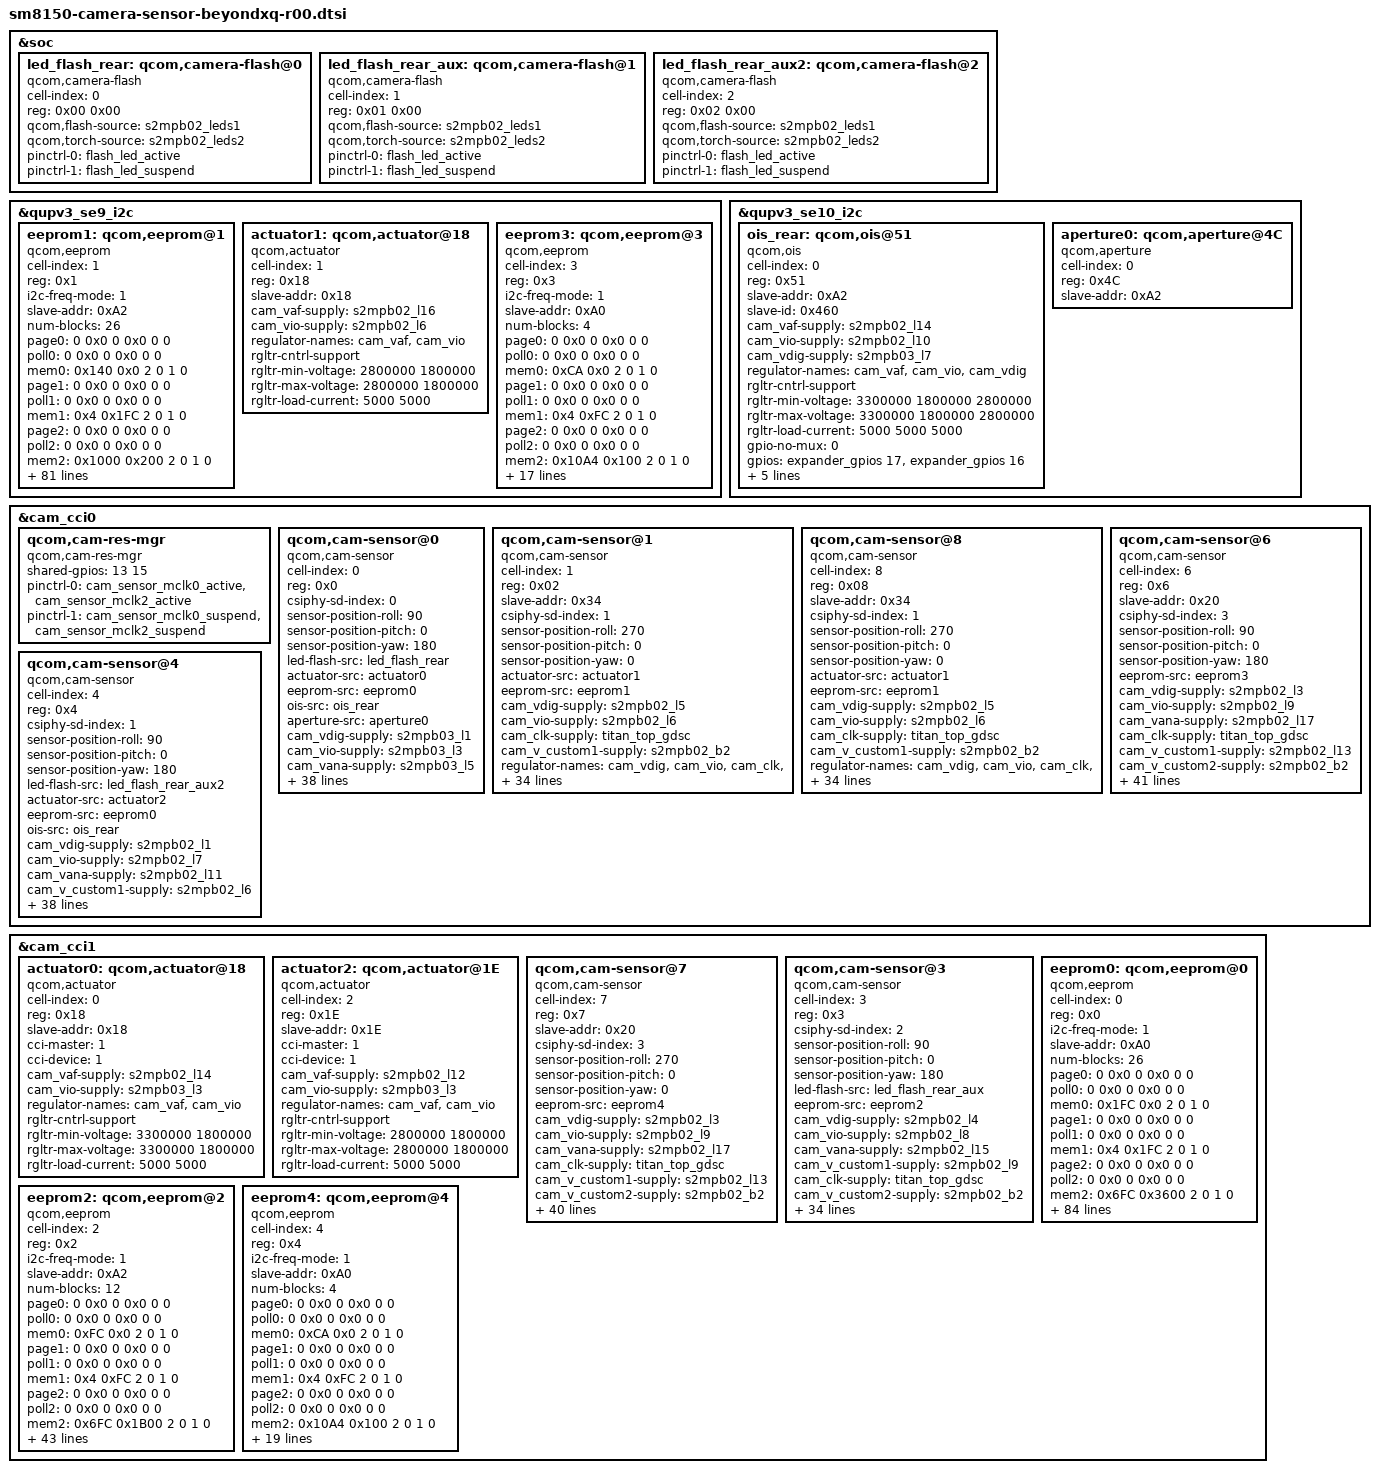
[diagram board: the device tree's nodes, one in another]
/*
 * Copyright (c) 2018, The Linux Foundation. All rights reserved.
 *
 * This program is free software; you can redistribute it and/or modify
 * it under the terms of the GNU General Public License version 2 and
 * only version 2 as published by the Free Software Foundation.
 *
 * This program is distributed in the hope that it will be useful,
 * but WITHOUT ANY WARRANTY; without even the implied warranty of
 * MERCHANTABILITY or FITNESS FOR A PARTICULAR PURPOSE.  See the
 * GNU General Public License for more details.
 */

&soc{
	led_flash_rear: qcom,camera-flash@0 {
		cell-index = <0>;
		reg = <0x00 0x00>;
		compatible = "qcom,camera-flash";
		qcom,flash-source = <&s2mpb02_leds1>;
		qcom,torch-source = <&s2mpb02_leds2>;
		pinctrl-names = "cam_default", "cam_suspend";
		pinctrl-0 = <&flash_led_active>;
		pinctrl-1 = <&flash_led_suspend>;
		status = "ok";
	};

	led_flash_rear_aux: qcom,camera-flash@1 {
		cell-index = <1>;
		reg = <0x01 0x00>;
		compatible = "qcom,camera-flash";
		qcom,flash-source = <&s2mpb02_leds1>;
		qcom,torch-source = <&s2mpb02_leds2>;
		pinctrl-names = "cam_default", "cam_suspend";
		pinctrl-0 = <&flash_led_active>;
		pinctrl-1 = <&flash_led_suspend>;
		status = "ok";
	};

	led_flash_rear_aux2: qcom,camera-flash@2 {
		cell-index = <2>;
		reg = <0x02 0x00>;
		compatible = "qcom,camera-flash";
		qcom,flash-source = <&s2mpb02_leds1>;
		qcom,torch-source = <&s2mpb02_leds2>;
		pinctrl-names = "cam_default", "cam_suspend";
		pinctrl-0 = <&flash_led_active>;
		pinctrl-1 = <&flash_led_suspend>;
		status = "ok";
	};
};

&qupv3_se9_i2c {
	status = "ok";

	eeprom1: qcom,eeprom@1 {
		cell-index = <1>;
		reg = <0x1>;
		compatible = "qcom,eeprom";
		i2c-freq-mode = <1>;
		slave-addr = <0xA2>;
		//eeprom-name= "n24c256";

		num-blocks = <26>;
		page0 = <0 0x0 0 0x0 0 0>;
		poll0 = <0 0x0 0 0x0 0 0>;
		mem0 = <0x140 0x0 2 0 1 0>;
		page1 = <0 0x0 0 0x0 0 0>;
		poll1 = <0 0x0 0 0x0 0 0>;
		mem1 = <0x4 0x1FC 2 0 1 0>;
		page2 = <0 0x0 0 0x0 0 0>;
		poll2 = <0 0x0 0 0x0 0 0>;
		mem2 = <0x1000 0x200 2 0 1 0>;
		page3 = <0 0x0 0 0x0 0 0>;
		poll3 = <0 0x0 0 0x0 0 0>;
		mem3 = <0x4 0x1200 2 0 1 0>;
		page4 = <0 0x0 0 0x0 0 0>;
		poll4 = <0 0x0 0 0x0 0 0>;
		mem4 = <0x420 0x1204 2 0 1 0>;
		page5 = <0 0x0 0 0x0 0 0>;
		poll5 = <0 0x0 0 0x0 0 0>;
		mem5 = <0x4 0x1624 2 0 1 0>;
		page6 = <0 0x0 0 0x0 0 0>;
		poll6 = <0 0x0 0 0x0 0 0>;
		mem6 = <0x2C 0x1630 2 0 1 0>;
		page7 = <0 0x0 0 0x0 0 0>;
		poll7 = <0 0x0 0 0x0 0 0>;
		mem7 = <0x4 0x165C 2 0 1 0>;
		page8 = <0 0x0 0 0x0 0 0>;
		poll8 = <0 0x0 0 0x0 0 0>;
		mem8 = <0x2C 0x1660 2 0 1 0>;
		page9 = <0 0x0 0 0x0 0 0>;
		poll9 = <0 0x0 0 0x0 0 0>;
		mem9 = <0x4 0x168C 2 0 1 0>;
		page10 = <0 0x0 0 0x0 0 0>;
		poll10 = <0 0x0 0 0x0 0 0>;
		mem10 = <0x6FC 0x1690 2 0 1 0>;
		page11 = <0 0x0 0 0x0 0 0>;
		poll11 = <0 0x0 0 0x0 0 0>;
		mem11 = <0x4 0x1D8C 2 0 1 0>;
		page12 = <0 0x0 0 0x0 0 0>;
		poll12 = <0 0x0 0 0x0 0 0>;
		mem12 = <0x1BE0 0x200 2 0 1 0>;
		page13 = <0 0x0 0 0x0 0 0>;
		poll13 = <0 0x0 0 0x0 0 0>;
		mem13 = <0x4 0x1DFC 2 0 1 0>;
		page14 = <0 0x0 0 0x0 0 0>;
		poll14 = <0 0x0 0 0x0 0 0>;
		mem14 = <0x2C 0x1E00 2 0 1 0>;
		page15 = <0 0x0 0 0x0 0 0>;
		poll15 = <0 0x0 0 0x0 0 0>;
		mem15 = <0x4 0x1E2C 2 0 1 0>;
		page16 = <0 0x0 0 0x0 0 0>;
		poll16 = <0 0x0 0 0x0 0 0>;
		mem16 = <0x2C 0x1E30 2 0 1 0>;
		page17 = <0 0x0 0 0x0 0 0>;
		poll17 = <0 0x0 0 0x0 0 0>;
		mem17 = <0x4 0x1E5C 2 0 1 0>;
		page18 = <0 0x0 0 0x0 0 0>;
		poll18 = <0 0x0 0 0x0 0 0>;
		mem18 = <0x6FC 0x1E60 2 0 1 0>;
		page19 = <0 0x0 0 0x0 0 0>;
		poll19 = <0 0x0 0 0x0 0 0>;
		mem19 = <0x4 0x255C 2 0 1 0>;
		page20 = <0 0x0 0 0x0 0 0>;
		poll20 = <0 0x0 0 0x0 0 0>;
		mem20 = <0x6C 0x2560 2 0 1 0>;
		page21 = <0 0x0 0 0x0 0 0>;
		poll21 = <0 0x0 0 0x0 0 0>;
		mem21 = <0x4 0x25CC 2 0 1 0>;
		page22 = <0 0x0 0 0x0 0 0>;
		poll22 = <0 0x0 0 0x0 0 0>;
		mem22 = <0x80C 0x25D0 2 0 1 0>;
		page23 = <0 0x0 0 0x0 0 0>;
		poll23 = <0 0x0 0 0x0 0 0>;
		mem23 = <0x4 0x2DDC 2 0 1 0>;
		page24 = <0 0x0 0 0x0 0 0>;
		poll24 = <0 0x0 0 0x0 0 0>;
		mem24 = <0xFE0 0x1E00 2 0 1 0>;
		page25 = <0 0x0 0 0x0 0 0>;
		poll25 = <0 0x0 0 0x0 0 0>;
		mem25 = <0x4 0x2DFC 2 0 1 0>;
		//total-size = <0x2E00>;

		qcom,cam-power-seq-type = "cam_vio";
		qcom,cam-power-seq-cfg-val = <1>;
		qcom,cam-power-seq-delay = <0>;

		cam_vio-supply = <&s2mpb02_l6>; /* VDD_VTCAM_IO_1P8 */
		regulator-names = "cam_vio";
		rgltr-cntrl-support;
		rgltr-min-voltage = <1800000>;
		rgltr-max-voltage = <1800000>;
		rgltr-load-current = <5000>;
		gpio-no-mux = <1>;
		sensor-position = <1>;
		sensor-mode = <0>;
		status = "ok";
	};

	actuator1: qcom,actuator@18 {
		cell-index = <1>;
		reg = <0x18>;
		slave-addr = <0x18>;
		compatible = "qcom,actuator";
		cam_vaf-supply = <&s2mpb02_l16>;
		cam_vio-supply = <&s2mpb02_l6>;
		regulator-names = "cam_vaf", "cam_vio";
		rgltr-cntrl-support;
		rgltr-min-voltage = <2800000 1800000>;
		rgltr-max-voltage = <2800000 1800000>;
		rgltr-load-current = <5000 5000>;
		status = "ok";
	};

	eeprom3: qcom,eeprom@3 {
		cell-index = <3>; /*REAR TOF EEPROM*/
		reg = <0x3>;
		compatible = "qcom,eeprom";
		i2c-freq-mode = <1>;
		slave-addr = <0xA0>;
		//eeprom-name= "n24c256";

		num-blocks = <4>;
		page0 = <0 0x0 0 0x0 0 0>;
		poll0 = <0 0x0 0 0x0 0 0>;
		mem0 = <0xCA 0x0 2 0 1 0>;
		page1 = <0 0x0 0 0x0 0 0>;
		poll1 = <0 0x0 0 0x0 0 0>;
		mem1 = <0x4 0xFC 2 0 1 0>;
		page2 = <0 0x0 0 0x0 0 0>;
		poll2 = <0 0x0 0 0x0 0 0>;
		mem2 = <0x10A4 0x100 2 0 1 0>;
		page3 = <0 0x0 0 0x0 0 0>;
		poll3 = <0 0x0 0 0x0 0 0>;
		mem3 = <0x4 0x18FC 2 0 1 0>;
		//total-size = <0x1900>;

		qcom,cam-power-seq-type = "cam_vio", "cam_v_custom1";
		qcom,cam-power-seq-cfg-val = <1 1>;
		qcom,cam-power-seq-delay = <0 0>;

		cam_vio-supply = <&s2mpb02_l6>; /* VDD_VTCAM_IO_1P8 */
		cam_v_custom1-supply = <&s2mpb02_l9>; /* VDD_TOF_IO_1P8 */
		regulator-names = "cam_vio", "cam_v_custom1";
		rgltr-cntrl-support;
		rgltr-min-voltage = <1800000 1800000>;
		rgltr-max-voltage = <1800000 1800000>;
		rgltr-load-current = <5000 5000>;
		gpio-no-mux = <1>;
		sensor-position = <0>;
		sensor-mode = <0>;
		status = "ok";
	};
};

&qupv3_se10_i2c {
	status = "ok";
	ois_rear: qcom,ois@51  {
		compatible = "qcom,ois";
		cell-index = <0>;
		reg = <0x51>;
		slave-addr = <0xA2>;
		slave-id = <0x460>;
		cam_vaf-supply = <&s2mpb02_l14>; /* VDD_MAINCAM_AF_3P3 */
		cam_vio-supply = <&s2mpb02_l10>; /* VDD_OIS_MCU_1P8 */
		cam_vdig-supply = <&s2mpb03_l7>; /* VDD_CAM_OIS_2P8 */
		regulator-names = "cam_vaf", "cam_vio", "cam_vdig";
		rgltr-cntrl-support;
		rgltr-min-voltage = <3300000 1800000 2800000>;
		rgltr-max-voltage = <3300000 1800000 2800000>;
		rgltr-load-current = <5000 5000 5000>;
		gpio-no-mux = <0>;
		gpios = <&expander_gpios 17 0>, // RESET
			<&expander_gpios 16 0>; // BOOT0
		gpio-reset = <0>;
		gpio-custom1 = <1>;
		gpio-req-tbl-num = <0 1>;
		gpio-req-tbl-flags = <0 0>;
		gpio-req-tbl-label = "MCU_RESET0", "MCU_BOOT0";
		status = "ok";
	};

	aperture0: qcom,aperture@4C {
		cell-index = <0>;
		reg = <0x4C>;
		compatible = "qcom,aperture";
		slave-addr = <0xA2>;
		status = "ok";
	};
};

&cam_cci0 {
	qcom,cam-res-mgr {
		compatible = "qcom,cam-res-mgr";
		shared-gpios = <13 15>;
		pinctrl-names = "cam_res_mgr_default", "cam_res_mgr_suspend";
		status = "ok";
		pinctrl-0 = <&cam_sensor_mclk0_active
		    &cam_sensor_mclk2_active>;
		pinctrl-1 = <&cam_sensor_mclk0_suspend
    		&cam_sensor_mclk2_suspend>;
	};

	qcom,cam-sensor@0 {
		cell-index = <0>; /*REAR MAIN*/
		compatible = "qcom,cam-sensor";
		reg = <0x0>;
		csiphy-sd-index = <0>;
		sensor-position-roll = <90>;
		sensor-position-pitch = <0>;
		sensor-position-yaw = <180>;
		led-flash-src = <&led_flash_rear>;
		actuator-src = <&actuator0>;
		eeprom-src = <&eeprom0>;
		ois-src = <&ois_rear>;
		aperture-src = <&aperture0>;
		cam_vdig-supply = <&s2mpb03_l1>;
		cam_vio-supply = <&s2mpb03_l3>;
		cam_vana-supply = <&s2mpb03_l5>;
		cam_v_custom1-supply = <&s2mpb03_l6>;
		cam_v_custom2-supply = <&s2mpb03_l2>;
		cam_v_custom3-supply = <&s2mpb03_l4>;
		cam_v_custom4-supply = <&s2mpb02_l9>; /* VDD_TOF_IO_1P8 */
		cam_clk-supply = <&titan_top_gdsc>;
		regulator-names = "cam_vdig", "cam_vio", "cam_vana", "cam_v_custom1", "cam_v_custom2", "cam_v_custom3", "cam_v_custom4", "cam_clk";
		rgltr-cntrl-support;
		rgltr-min-voltage = <1025000 1800000 2400000 2800000 1100000 1025000 1800000 0>;
		rgltr-max-voltage = <1025000 1800000 2400000 2800000 1100000 1025000 1800000 0>;
		rgltr-load-current = <200000 200000 5000 200000 5000 5000 5000 0>;
		gpio-no-mux = <0>;
		use-shared-clk;
		gpios = <&tlmm 13 0>, /* MCLK */
			<&expander_gpios 12 0>; /* RESET */
		gpio-reset = <1>;
		gpio-req-tbl-num = <0 1>;
		gpio-req-tbl-flags = <1 0>;
		gpio-req-tbl-label = "CAMIF_MCLK0",
					"CAM_RESET0";
		sensor-mode = <0>;
		cci-master = <0>;
		status = "ok";
		clocks = <&clock_camcc CAM_CC_MCLK0_CLK>;
		clock-names = "cam_clk";
		clock-cntl-level = "turbo";
		clock-rates = <19200000>;

		cam,isp = <0>;                  // 0 : INT , 1 : EXT , 2 : SOC
		cam,cal_memory = <2>;           // 0 : N , 1 : FROM , 2 : EEPROM , 3 : OTP
		cam,read_version = <1>;         // 0 : SYSFS , 1 : CAMON
		cam,core_voltage = <1>;         // 0 : N , 1 : Y
		cam,upgrade = <2>;              // 0 : N , 1 : SYSFS , 2 : CAMON
		cam,fw_write = <3>;             // 0 : N , 1 : OS , 2 : SD , 3 : ALL
		cam,fw_dump = <1>;              // 0 : N , 1 : Y
		cam,companion_chip = <0>;       // 0 : N , 1 : Y
		cam,ois = <1>;                  // 0 : N , 1 : Y
		cam,dual_open = <0>;            // 0 : N , 1 : Y
		cam,valid = <1>;                // 0 : N , 1 : Y
	};

 	qcom,cam-sensor@1 {
		cell-index = <1>; //VT 10M
		compatible = "qcom,cam-sensor";
		reg = <0x02>;
		slave-addr = <0x34>;
		csiphy-sd-index = <1>;
		sensor-position-roll = <270>;
		sensor-position-pitch = <0>;
		sensor-position-yaw = <0>;
		actuator-src = <&actuator1>;
		eeprom-src = <&eeprom1>;
		cam_vdig-supply = <&s2mpb02_l5>;
		cam_vio-supply = <&s2mpb02_l6>;
		cam_clk-supply = <&titan_top_gdsc>;
		cam_v_custom1-supply = <&s2mpb02_b2>;
		regulator-names = "cam_vdig", "cam_vio", "cam_clk", "cam_v_custom1";
		rgltr-cntrl-support;
		rgltr-min-voltage = <1050000 1800000 0 1300000>;
		rgltr-max-voltage = <1050000 1800000 0 1300000>;
		rgltr-load-current = <200000 200000 0 200000>;
		gpio-no-mux = <0>;
		use-shared-clk;
		pinctrl-names = "cam_default", "cam_suspend";
		pinctrl-0 = <&cam_sensor_active_front
			&cam_sensor_mipi_sw_active>;
		pinctrl-1 = <&cam_sensor_suspend_front
			&cam_sensor_mipi_sw_suspend>;
		gpios = <&tlmm 15 0>,
			<&tlmm 82 0>,
			<&tlmm 116 0>;  //SUBCAM_SEL
		gpio-reset = <1>;
		gpio-custom1 = <2>;
		gpio-req-tbl-num = <0 1 2>;
		gpio-req-tbl-flags = <1 0 0>;
		gpio-req-tbl-label = "CAMIF_MCLK2",
					"CAM_RESET2",
					"SUBCAM_SEL";
                sensor-mode = <0>;
		cci-master = <1>;
		status = "ok";
		clocks = <&clock_camcc CAM_CC_MCLK2_CLK>;
		clock-names = "cam_clk";
		clock-cntl-level = "turbo";
		clock-rates = <24000000>;

		cam,isp = <0>;                  // 0 : INT , 1 : EXT , 2 : SOC
		cam,cal_memory = <2>;           // 0 : N , 1 : FROM , 2 : EEPROM , 3 : OTP
		cam,read_version = <0>;         // 0 : SYSFS , 1 : CAMON
		cam,core_voltage = <0>;         // 0 : N , 1 : Y
		cam,upgrade = <0>;              // 0 : N , 1 : SYSFS , 2 : CAMON
		cam,fw_write = <0>;             // 0 : N , 1 : OS , 2 : SD , 3 : ALL
		cam,fw_dump = <0>;              // 0 : N , 1 : Y
		cam,companion_chip = <0>;       // 0 : N , 1 : Y
		cam,ois = <0>;                  // 0 : N , 1 : Y
		cam,dual_open = <0>;            // 0 : N , 1 : Y
		cam,valid = <1>;                // 0 : N , 1 : Y
	};

 	qcom,cam-sensor@8 {
		cell-index = <8>; //VT 10M FULL
		compatible = "qcom,cam-sensor";
		reg = <0x08>;
		slave-addr = <0x34>;
		csiphy-sd-index = <1>;
		sensor-position-roll = <270>;
		sensor-position-pitch = <0>;
		sensor-position-yaw = <0>;
		actuator-src = <&actuator1>;
		eeprom-src = <&eeprom1>;
		cam_vdig-supply = <&s2mpb02_l5>;
		cam_vio-supply = <&s2mpb02_l6>;
		cam_clk-supply = <&titan_top_gdsc>;
		cam_v_custom1-supply = <&s2mpb02_b2>;
		regulator-names = "cam_vdig", "cam_vio", "cam_clk", "cam_v_custom1";
		rgltr-cntrl-support;
		rgltr-min-voltage = <1050000 1800000 0 1300000>;
		rgltr-max-voltage = <1050000 1800000 0 1300000>;
		rgltr-load-current = <200000 200000 0 200000>;
		gpio-no-mux = <0>;
		use-shared-clk;
		pinctrl-names = "cam_default", "cam_suspend";
		pinctrl-0 = <&cam_sensor_active_front
			&cam_sensor_mipi_sw_active>;
		pinctrl-1 = <&cam_sensor_suspend_front
			&cam_sensor_mipi_sw_suspend>;
		gpios = <&tlmm 15 0>,
			<&tlmm 82 0>,
			<&tlmm 116 0>;  //SUBCAM_SEL
		gpio-reset = <1>;
		gpio-custom1 = <2>;
		gpio-req-tbl-num = <0 1 2>;
		gpio-req-tbl-flags = <1 0 0>;
		gpio-req-tbl-label = "CAMIF_MCLK2",
					"CAM_RESET2",
					"SUBCAM_SEL";
                sensor-mode = <0>;
		cci-master = <1>;
		status = "ok";
		clocks = <&clock_camcc CAM_CC_MCLK2_CLK>;
		clock-names = "cam_clk";
		clock-cntl-level = "turbo";
		clock-rates = <24000000>;

		cam,isp = <0>;                  // 0 : INT , 1 : EXT , 2 : SOC
		cam,cal_memory = <2>;           // 0 : N , 1 : FROM , 2 : EEPROM , 3 : OTP
		cam,read_version = <0>;         // 0 : SYSFS , 1 : CAMON
		cam,core_voltage = <0>;         // 0 : N , 1 : Y
		cam,upgrade = <0>;              // 0 : N , 1 : SYSFS , 2 : CAMON
		cam,fw_write = <0>;             // 0 : N , 1 : OS , 2 : SD , 3 : ALL
		cam,fw_dump = <0>;              // 0 : N , 1 : Y
		cam,companion_chip = <0>;       // 0 : N , 1 : Y
		cam,ois = <0>;                  // 0 : N , 1 : Y
		cam,dual_open = <0>;            // 0 : N , 1 : Y
		cam,valid = <1>;                // 0 : N , 1 : Y
	};
	qcom,cam-sensor@6 {
		cell-index = <6>; // REAR TOF
		compatible = "qcom,cam-sensor";
		reg = <0x6>;
		slave-addr = <0x20>;
		csiphy-sd-index = <3>;
		sensor-position-roll = <90>;
		sensor-position-pitch = <0>;
		sensor-position-yaw = <180>;
		eeprom-src = <&eeprom3>;
		cam_vdig-supply = <&s2mpb02_l3>;
		cam_vio-supply = <&s2mpb02_l9>;
		cam_vana-supply = <&s2mpb02_l17>;
		cam_clk-supply = <&titan_top_gdsc>;
		cam_v_custom1-supply = <&s2mpb02_l13>;
		cam_v_custom2-supply = <&s2mpb02_b2>;
		cam_v_custom3-supply = <&s2mpb02_l6>;
		regulator-names = "cam_vdig", "cam_vio", "cam_vana", "cam_clk", "cam_v_custom1", "cam_v_custom2", "cam_v_custom3";
		rgltr-cntrl-support;
		rgltr-min-voltage = <1200000 1800000 2800000 0 3300000 1300000 1800000>;
		rgltr-max-voltage = <1200000 1800000 2800000 0 3300000 1300000 1800000>;
		rgltr-load-current = <200000 200000 5000 0 200000 200000 200000>;
		gpio-no-mux = <0>;
		pinctrl-names = "cam_default", "cam_suspend";
		pinctrl-0 = <&cam_sensor_mclk3_active
			&cam_sensor_mipi_sw1_active>;
		pinctrl-1 = <&cam_sensor_mclk3_suspend
			&cam_sensor_mipi_sw1_suspend>;
		gpios = <&tlmm 16 0>,  // MCLK
			<&expander_gpios 15 0>, // TOF RESET
			<&tlmm 7 0>,
			<&expander_gpios 20 0>; // TOF BB ENABLE;
		gpio-reset = <1>;
		gpio-custom1 = <2>;
		gpio-custom2 = <3>;
		gpio-req-tbl-num = <0 1 2 3>;
		gpio-req-tbl-flags = <1 0 0 0>;
		gpio-req-tbl-label = "CAMIF_MCLK3",
					"CAM_RESET3",
					"TOFCAM_SEL",
					"TOF_BB_ENABLE";
        sensor-mode = <0>;
		cci-master = <1>;
		status = "ok";
		clocks = <&clock_camcc CAM_CC_MCLK3_CLK>;
		clock-names = "cam_clk";
		clock-cntl-level = "turbo";
		clock-rates = <24000000>;

		cam,isp = <0>;                  // 0 : INT , 1 : EXT , 2 : SOC
		cam,cal_memory = <0>;           // 0 : N , 1 : FROM , 2 : EEPROM , 3 : OTP
		cam,read_version = <0>;         // 0 : SYSFS , 1 : CAMON
		cam,core_voltage = <0>;         // 0 : N , 1 : Y
		cam,upgrade = <0>;              // 0 : N , 1 : SYSFS , 2 : CAMON
		cam,fw_write = <0>;             // 0 : N , 1 : OS , 2 : SD , 3 : ALL
		cam,fw_dump = <0>;              // 0 : N , 1 : Y
		cam,companion_chip = <0>;       // 0 : N , 1 : Y
		cam,ois = <0>;                  // 0 : N , 1 : Y
		cam,dual_open = <0>;            // 0 : N , 1 : Y
		cam,valid = <1>;                // 0 : N , 1 : Y
	};

	qcom,cam-sensor@4 {
		cell-index = <4>; /* REAR TELE */
		compatible = "qcom,cam-sensor";
		reg = <0x4>;
		csiphy-sd-index = <1>;
		sensor-position-roll = <90>;
		sensor-position-pitch = <0>;
		sensor-position-yaw = <180>;
		led-flash-src = <&led_flash_rear_aux2>;
		actuator-src = <&actuator2>;
		eeprom-src = <&eeprom0>;
		ois-src = <&ois_rear>;
		cam_vdig-supply = <&s2mpb02_l1>;
		cam_vio-supply = <&s2mpb02_l7>;
		cam_vana-supply = <&s2mpb02_l11>;
		cam_v_custom1-supply = <&s2mpb02_l6>; /* VDD_VT10M_IO_1P8 */
		cam_clk-supply = <&titan_top_gdsc>;
		cam_v_custom2-supply = <&s2mpb02_b2>;
		regulator-names = "cam_vdig", "cam_vio", "cam_vana", "cam_v_custom1", "cam_clk", "cam_v_custom2";
		rgltr-cntrl-support;
		rgltr-min-voltage = <1025000 1800000 2800000 1800000 0 1300000>;
		rgltr-max-voltage = <1025000 1800000 2800000 1800000 0 1300000>;
		rgltr-load-current = <200000 200000 200000 5000 0 200000>;
		gpio-no-mux = <0>;
		use-shared-clk;
		pinctrl-names = "cam_default", "cam_suspend";
		pinctrl-0 = <&cam_sensor_mipi_sw_active>;
		pinctrl-1 = <&cam_sensor_mipi_sw_suspend>;
		gpios = <&tlmm 13 0>, /* MCLK */
			<&expander_gpios 14 0>, /* RESET */
			<&tlmm 116 0>; /* SUBCAM_SEL */
		gpio-reset = <1>;
		gpio-custom1 = <2>;
		gpio-req-tbl-num = <0 1 2>;
		gpio-req-tbl-flags = <1 0 1>;
		gpio-req-tbl-label = "CAMIF_MCLK0",
					"CAM_SUB_RESET",
					"SUBCAM_SEL";
		sensor-mode = <0>;
		cci-master = <1>;
		status = "ok";
		clocks = <&clock_camcc CAM_CC_MCLK0_CLK>;
		clock-names = "cam_clk";
		clock-cntl-level = "turbo";
		clock-rates = <19200000>;

		cam,isp = <0>;                  // 0 : INT , 1 : EXT , 2 : SOC
		cam,cal_memory = <2>;           // 0 : N , 1 : FROM , 2 : EEPROM , 3 : OTP
		cam,read_version = <0>;         // 0 : SYSFS , 1 : CAMON
		cam,core_voltage = <0>;         // 0 : N , 1 : Y
		cam,upgrade = <0>;              // 0 : N , 1 : SYSFS , 2 : CAMON
		cam,fw_write = <0>;             // 0 : N , 1 : OS , 2 : SD , 3 : ALL
		cam,fw_dump = <0>;              // 0 : N , 1 : Y
		cam,companion_chip = <0>;       // 0 : N , 1 : Y
		cam,ois = <1>;                  // 0 : N , 1 : Y
		cam,dual_open = <0>;            // 0 : N , 1 : Y
		cam,valid = <1>;                // 0 : N , 1 : Y
	};
};

&cam_cci1 {
	actuator0: qcom,actuator@18 { /* Wide */
		cell-index = <0>;
		reg = <0x18>;
		slave-addr = <0x18>;
		compatible = "qcom,actuator";
		cci-master = <1>;
		cci-device = <1>;
		cam_vaf-supply = <&s2mpb02_l14>;
		cam_vio-supply = <&s2mpb03_l3>;
		regulator-names = "cam_vaf", "cam_vio";
		rgltr-cntrl-support;
		rgltr-min-voltage = <3300000 1800000>;
		rgltr-max-voltage = <3300000 1800000>;
		rgltr-load-current = <5000 5000>;
		status = "ok";
	};

	actuator2: qcom,actuator@1E { /* Tele */
		cell-index = <2>;
		reg = <0x1E>;
		slave-addr = <0x1E>;
		compatible = "qcom,actuator";
		cci-master = <1>;
		cci-device = <1>;
		cam_vaf-supply = <&s2mpb02_l12>;
		cam_vio-supply = <&s2mpb03_l3>;
		regulator-names = "cam_vaf", "cam_vio";
		rgltr-cntrl-support;
		rgltr-min-voltage = <2800000 1800000>;
		rgltr-max-voltage = <2800000 1800000>;
		rgltr-load-current = <5000 5000>;
		status = "ok";
	};

	qcom,cam-sensor@7 {
		cell-index = <7>;   //FRONT TOF
		compatible = "qcom,cam-sensor";
		reg = <0x7>;
		slave-addr = <0x20>;
		csiphy-sd-index = <3>;
		sensor-position-roll = <270>;
		sensor-position-pitch = <0>;
		sensor-position-yaw = <0>;
		eeprom-src = <&eeprom4>;
		cam_vdig-supply = <&s2mpb02_l3>;
		cam_vio-supply = <&s2mpb02_l9>;
		cam_vana-supply = <&s2mpb02_l17>;
		cam_clk-supply = <&titan_top_gdsc>;
		cam_v_custom1-supply = <&s2mpb02_l13>;
		cam_v_custom2-supply = <&s2mpb02_b2>;
		regulator-names = "cam_vdig", "cam_vio", "cam_vana", "cam_clk", "cam_v_custom1", "cam_v_custom2";
		rgltr-cntrl-support;
		rgltr-min-voltage = <1200000 1800000 2800000 0 3300000 1300000>;
		rgltr-max-voltage = <1200000 1800000 2800000 0 3300000 1300000>;
		rgltr-load-current = <200000 200000 5000 0 200000 200000>;
		gpio-no-mux = <0>;
		pinctrl-names = "cam_default", "cam_suspend";
		pinctrl-0 = <&cam_sensor_mclk3_active
			&cam_sensor_mipi_sw1_active>;
		pinctrl-1 = <&cam_sensor_mclk3_suspend
			&cam_sensor_mipi_sw1_suspend>;
		gpios = <&tlmm 16 0>,  // MCLK
			<&expander_gpios 15 0>, // TOF RESET
			<&tlmm 7 0>,
			<&expander_gpios 20 0>; // TOF BB ENABLE;
		gpio-reset = <1>;
		gpio-custom1 = <2>;
		gpio-custom2 = <3>;
		gpio-req-tbl-num = <0 1 2 3>;
		gpio-req-tbl-flags = <1 0 0 0>;
		gpio-req-tbl-label = "CAMIF_MCLK3",
					"CAM_RESET3",
					"TOFCAM_SEL",
					"TOF_BB_ENABLE";
        sensor-mode = <0>;
		cci-master = <0>;
		cci-device = <1>;
		status = "ok";
		clocks = <&clock_camcc CAM_CC_MCLK3_CLK>;
		clock-names = "cam_clk";
		clock-cntl-level = "turbo";
		clock-rates = <24000000>;

		cam,isp = <0>;                  // 0 : INT , 1 : EXT , 2 : SOC
		cam,cal_memory = <0>;           // 0 : N , 1 : FROM , 2 : EEPROM , 3 : OTP
		cam,read_version = <0>;         // 0 : SYSFS , 1 : CAMON
		cam,core_voltage = <0>;         // 0 : N , 1 : Y
		cam,upgrade = <0>;              // 0 : N , 1 : SYSFS , 2 : CAMON
		cam,fw_write = <0>;             // 0 : N , 1 : OS , 2 : SD , 3 : ALL
		cam,fw_dump = <0>;              // 0 : N , 1 : Y
		cam,companion_chip = <0>;       // 0 : N , 1 : Y
		cam,ois = <0>;                  // 0 : N , 1 : Y
		cam,dual_open = <0>;            // 0 : N , 1 : Y
		cam,valid = <1>;                // 0 : N , 1 : Y
	};

	qcom,cam-sensor@3 {
		cell-index = <3>; /* REAR SW */
		compatible = "qcom,cam-sensor";
		reg = <0x3>;
		csiphy-sd-index = <2>;
		sensor-position-roll = <90>;
		sensor-position-pitch = <0>;
		sensor-position-yaw = <180>;
		led-flash-src = <&led_flash_rear_aux>;
		eeprom-src = <&eeprom2>;
		cam_vdig-supply = <&s2mpb02_l4>;
		cam_vio-supply = <&s2mpb02_l8>;
		cam_vana-supply = <&s2mpb02_l15>;
		cam_v_custom1-supply = <&s2mpb02_l9>; /* VDD_VT8M_IO_1P8 */
		cam_clk-supply = <&titan_top_gdsc>;
		cam_v_custom2-supply = <&s2mpb02_b2>;
		regulator-names = "cam_vdig", "cam_vio", "cam_vana", "cam_v_custom1", "cam_clk", "cam_v_custom2";
		rgltr-cntrl-support;
		rgltr-min-voltage = <1050000 1800000 2800000 1800000 0 1300000>;
		rgltr-max-voltage = <1050000 1800000 2800000 1800000 0 1300000>;
		rgltr-load-current = <200000 200000 200000 5000 0 200000>;
		gpio-no-mux = <0>;
		pinctrl-names = "cam_default", "cam_suspend";
		pinctrl-0 = <&cam_sensor_mclk1_active>;
		pinctrl-1 = <&cam_sensor_mclk1_suspend>;
	        gpios = <&tlmm 14 0>, /* MCLK */
			<&expander_gpios 13 0>; /* RESET */
                gpio-reset = <1>;
		gpio-req-tbl-num = <0 1>;
		gpio-req-tbl-flags = <1 0>;
		gpio-req-tbl-label = "CAMIF_MCLK1",
					"CAM_RESET1";
		sensor-mode = <0>;
		cci-master = <0>;
		cci-device = <1>;
		status = "ok";
		clocks = <&clock_camcc CAM_CC_MCLK1_CLK>;
		clock-names = "cam_clk";
		clock-cntl-level = "turbo";
		clock-rates = <24000000>;

		cam,isp = <0>;                  // 0 : INT , 1 : EXT , 2 : SOC
		cam,cal_memory = <2>;           // 0 : N , 1 : FROM , 2 : EEPROM , 3 : OTP
		cam,read_version = <0>;         // 0 : SYSFS , 1 : CAMON
		cam,core_voltage = <0>;         // 0 : N , 1 : Y
		cam,upgrade = <0>;              // 0 : N , 1 : SYSFS , 2 : CAMON
		cam,fw_write = <0>;             // 0 : N , 1 : OS , 2 : SD , 3 : ALL
		cam,fw_dump = <0>;              // 0 : N , 1 : Y
		cam,companion_chip = <0>;       // 0 : N , 1 : Y
		cam,ois = <0>;                  // 0 : N , 1 : Y
		cam,dual_open = <0>;            // 0 : N , 1 : Y
		cam,valid = <1>;                // 0 : N , 1 : Y
	};

	eeprom0: qcom,eeprom@0 {
		cell-index = <0>;
		reg = <0x0>;
		compatible = "qcom,eeprom";
		i2c-freq-mode = <1>;
		slave-addr = <0xA0>;
		//eeprom-name= "cat24c512c8utr";

		num-blocks = <26>;
		page0 = <0 0x0 0 0x0 0 0>;
		poll0 = <0 0x0 0 0x0 0 0>;
		mem0 = <0x1FC 0x0 2 0 1 0>;
		page1 = <0 0x0 0 0x0 0 0>;
		poll1 = <0 0x0 0 0x0 0 0>;
		mem1 = <0x4 0x1FC 2 0 1 0>;
		page2 = <0 0x0 0 0x0 0 0>;
		poll2 = <0 0x0 0 0x0 0 0>;
		mem2 = <0x6FC 0x3600 2 0 1 0>;
		page3 = <0 0x0 0 0x0 0 0>;
		poll3 = <0 0x0 0 0x0 0 0>;
		mem3 = <0x4 0x3CFC 2 0 1 0>;
		page4 = <0 0x0 0 0x0 0 0>;
		poll4 = <0 0x0 0 0x0 0 0>;
		mem4 = <0x6FC 0x3D00 2 0 1 0>;
		page5 = <0 0x0 0 0x0 0 0>;
		poll5 = <0 0x0 0 0x0 0 0>;
		mem5 = <0x4 0x43FC 2 0 1 0>;
		page6 = <0 0x0 0 0x0 0 0>;
		poll6 = <0 0x0 0 0x0 0 0>;
		mem6 = <0x1000 0x4400 2 0 1 0>;
		page7 = <0 0x0 0 0x0 0 0>;
		poll7 = <0 0x0 0 0x0 0 0>;
		mem7 = <0x4 0x5400 2 0 1 0>;
		page8 = <0 0x0 0 0x0 0 0>;
		poll8 = <0 0x0 0 0x0 0 0>;
		mem8 = <0x800 0x5404 2 0 1 0>;
		page9 = <0 0x0 0 0x0 0 0>;
		poll9 = <0 0x0 0 0x0 0 0>;
		mem9 = <0x4 0x5C04 2 0 1 0>;
		page10 = <0 0x0 0 0x0 0 0>;
		poll10 = <0 0x0 0 0x0 0 0>;
		mem10 = <0x1000 0x5C10 2 0 1 0>;
		page11 = <0 0x0 0 0x0 0 0>;
		poll11 = <0 0x0 0 0x0 0 0>;
		mem11 = <0x4 0x6C10 2 0 1 0>;
		page12 = <0 0x0 0 0x0 0 0>;
		poll12 = <0 0x0 0 0x0 0 0>;
		mem12 = <0x800 0x6C14 2 0 1 0>;
		page13 = <0 0x0 0 0x0 0 0>;
		poll13 = <0 0x0 0 0x0 0 0>;
		mem13 = <0x4 0x7414 2 0 1 0>;
		page14 = <0 0x0 0 0x0 0 0>;
		poll14 = <0 0x0 0 0x0 0 0>;
		mem14 = <0x2C 0x7420 2 0 1 0>;
		page15 = <0 0x0 0 0x0 0 0>;
		poll15 = <0 0x0 0 0x0 0 0>;
		mem15 = <0x4 0x744C 2 0 1 0>;
		page16 = <0 0x0 0 0x0 0 0>;
		poll16 = <0 0x0 0 0x0 0 0>;
		mem16 = <0x3C 0x7450 2 0 1 0>;
		page17 = <0 0x0 0 0x0 0 0>;
		poll17 = <0 0x0 0 0x0 0 0>;
		mem17 = <0x4 0x748C 2 0 1 0>;
		page18 = <0 0x0 0 0x0 0 0>;
		poll18 = <0 0x0 0 0x0 0 0>;
		mem18 = <0x3C 0x7490 2 0 1 0>;
		page19 = <0 0x0 0 0x0 0 0>;
		poll19 = <0 0x0 0 0x0 0 0>;
		mem19 = <0x4 0x74CC 2 0 1 0>;
		page20 = <0 0x0 0 0x0 0 0>;
		poll20 = <0 0x0 0 0x0 0 0>;
		mem20 = <0x6C 0x74D0 2 0 1 0>;
		page21 = <0 0x0 0 0x0 0 0>;
		poll21 = <0 0x0 0 0x0 0 0>;
		mem21 = <0x4 0x753C 2 0 1 0>;
		page22 = <0 0x0 0 0x0 0 0>;
		poll22 = <0 0x0 0 0x0 0 0>;
		mem22 = <0x5C 0x7540 2 0 1 0>;
		page23 = <0 0x0 0 0x0 0 0>;
		poll23 = <0 0x0 0 0x0 0 0>;
		mem23 = <0x4 0x759C 2 0 1 0>;
		page24 = <0 0x0 0 0x0 0 0>;
		poll24 = <0 0x0 0 0x0 0 0>;
		mem24 = <0x31E0 0x4400 2 0 1 0>;
		page25 = <0 0x0 0 0x0 0 0>;
		poll25 = <0 0x0 0 0x0 0 0>;
		mem25 = <0x4 0x75FC 2 0 1 0>;
		//total-size = <0x7600>;
		multimodule-support;

		cci-master = <1>;
		cci-device = <1>;
		qcom,cam-power-seq-type = "cam_vio";
		qcom,cam-power-seq-cfg-val = <1>;
		qcom,cam-power-seq-delay = <0>;
		cam_vio-supply = <&s2mpb03_l3>; /* VDD_MAINCAM_IO_1P8 */
		regulator-names = "cam_vio";
		rgltr-cntrl-support;
		rgltr-min-voltage = <1800000>;
		rgltr-max-voltage = <1800000>;
		rgltr-load-current = <5000>;
		gpio-no-mux = <1>;
		sensor-position = <0>;
		sensor-mode = <0>;
		status = "ok";
	};

	eeprom2: qcom,eeprom@2 {
		cell-index = <2>;
		reg = <0x2>;
		compatible = "qcom,eeprom";
		i2c-freq-mode = <1>;
		slave-addr = <0xA2>;
		//eeprom-name= "gt24p128ca2";

		num-blocks = <12>;
		page0 = <0 0x0 0 0x0 0 0>;
		poll0 = <0 0x0 0 0x0 0 0>;
		mem0 = <0xFC 0x0 2 0 1 0>;
		page1 = <0 0x0 0 0x0 0 0>;
		poll1 = <0 0x0 0 0x0 0 0>;
		mem1 = <0x4 0xFC 2 0 1 0>;
		page2 = <0 0x0 0 0x0 0 0>;
		poll2 = <0 0x0 0 0x0 0 0>;
		mem2 = <0x6FC 0x1B00 2 0 1 0>;
		page3 = <0 0x0 0 0x0 0 0>;
		poll3 = <0 0x0 0 0x0 0 0>;
		mem3 = <0x4 0x21FC 2 0 1 0>;
		page4 = <0 0x0 0 0x0 0 0>;
		poll4 = <0 0x0 0 0x0 0 0>;
		mem4 = <0x3C 0x2200 2 0 1 0>;
		page5 = <0 0x0 0 0x0 0 0>;
		poll5 = <0 0x0 0 0x0 0 0>;
		mem5 = <0x4 0x223C 2 0 1 0>;
		page6 = <0 0x0 0 0x0 0 0>;
		poll6 = <0 0x0 0 0x0 0 0>;
		mem6 = <0x6C 0x2240 2 0 1 0>;
		page7 = <0 0x0 0 0x0 0 0>;
		poll7 = <0 0x0 0 0x0 0 0>;
		mem7 = <0x4 0x22AC 2 0 1 0>;
		page8 = <0 0x0 0 0x0 0 0>;
		poll8 = <0 0x0 0 0x0 0 0>;
		mem8 = <0x80C 0x22B0 2 0 1 0>;
		page9 = <0 0x0 0 0x0 0 0>;
		poll9 = <0 0x0 0 0x0 0 0>;
		mem9 = <0x4 0x2ABC 2 0 1 0>;
		page10 = <0 0x0 0 0x0 0 0>;
		poll10 = <0 0x0 0 0x0 0 0>;
		mem10 = <0x29E0 0x100 2 0 1 0>;
		page11 = <0 0x0 0 0x0 0 0>;
		poll11 = <0 0x0 0 0x0 0 0>;
		mem11 = <0x4 0x2AFC 2 0 1 0>;
		//total-size = <0x2B00>;

		cci-master = <0>;
		cci-device = <1>;

		qcom,cam-power-seq-type = "cam_vio", "cam_v_custom1";
		qcom,cam-power-seq-cfg-val = <1 1>;
		qcom,cam-power-seq-delay = <0 0>;

		cam_vio-supply = <&s2mpb02_l9>; /* VDD_VT8M_IO_1P8 */
		cam_v_custom1-supply = <&s2mpb02_l8>; /* VDD_SWCAM_IO_1P8 */
		regulator-names = "cam_vio", "cam_v_custom1";
		rgltr-cntrl-support;
		rgltr-min-voltage = <1800000 1800000>;
		rgltr-max-voltage = <1800000 1800000>;
		rgltr-load-current = <5000 5000>;
		gpio-no-mux = <1>;
		sensor-position = <0>;
		sensor-mode = <0>;
		status = "ok";
	};

	eeprom4: qcom,eeprom@4 {
		cell-index = <4>; /*FRONT TOF EEPROM*/
		reg = <0x4>;
		compatible = "qcom,eeprom";
		i2c-freq-mode = <1>;
		slave-addr = <0xA0>;
		//eeprom-name= "cat24c512c8utr";

		num-blocks = <4>;
		page0 = <0 0x0 0 0x0 0 0>;
		poll0 = <0 0x0 0 0x0 0 0>;
		mem0 = <0xCA 0x0 2 0 1 0>;
		page1 = <0 0x0 0 0x0 0 0>;
		poll1 = <0 0x0 0 0x0 0 0>;
		mem1 = <0x4 0xFC 2 0 1 0>;
		page2 = <0 0x0 0 0x0 0 0>;
		poll2 = <0 0x0 0 0x0 0 0>;
		mem2 = <0x10A4 0x100 2 0 1 0>;
		page3 = <0 0x0 0 0x0 0 0>;
		poll3 = <0 0x0 0 0x0 0 0>;
		mem3 = <0x4 0x18FC 2 0 1 0>;
		//total-size = <0x1900>;

		cci-master = <1>;
		cci-device = <1>;
		qcom,cam-power-seq-type = "cam_vio", "cam_v_custom1";
		qcom,cam-power-seq-cfg-val = <1 1>;
		qcom,cam-power-seq-delay = <0 0>;
		cam_vio-supply = <&s2mpb03_l3>; /* VDD_MAINCAM_IO_1P8 */
		cam_v_custom1-supply = <&s2mpb02_l9>; /* VDD_TOF_IO_1P8 */
		regulator-names = "cam_vio", "cam_v_custom1";
		rgltr-cntrl-support;
		rgltr-min-voltage = <1800000 1800000>;
		rgltr-max-voltage = <1800000 1800000>;
		rgltr-load-current = <5000 5000>;
		gpio-no-mux = <1>;
		sensor-position = <1>;
		sensor-mode = <0>;
		status = "ok";
	};
};
